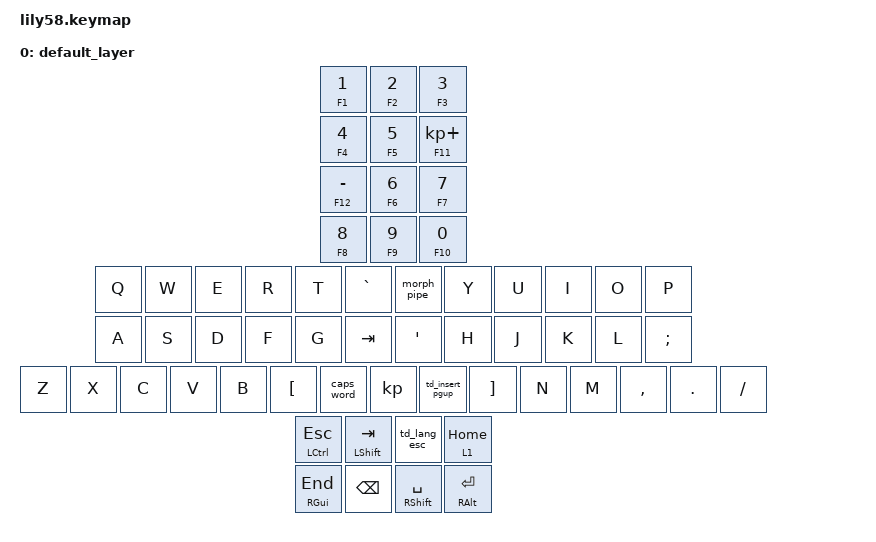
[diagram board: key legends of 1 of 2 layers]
/*
 * Copyright (c) 2020 The ZMK Contributors
 *
 * SPDX-License-Identifier: MIT
 */

#include <behaviors.dtsi>
#include <dt-bindings/zmk/bt.h>
#include <dt-bindings/zmk/keys.h>

/ {
  macros {
    lang: lang {
      compatible = "zmk,behavior-macro";
      #binding-cells = <0>;
      bindings =
        <&macro_press &kp LCTRL>,
        <&macro_tap &kp LSHFT>,
        <&macro_release &kp LCTRL>;
    };
    expipe: expipe {
      compatible = "zmk,behavior-macro";
      #binding-cells = <0>;
      bindings =
        <&macro_tap &kp PIPE>,
        <&macro_tap &kp GT>;
    };
  };
};

/ {
    behaviors {
      ht_tp: ht_tp {
        compatible = "zmk,behavior-hold-tap";
        #binding-cells = <2>;
        flavor = "tap-preferred";
        tapping-term-ms = <500>;
        quick-tap-ms = <500>;
        bindings = <&kp>, <&kp>;
      };
      td_lang_esc: td_lang_esc {
        compatible = "zmk,behavior-tap-dance";
        #binding-cells = <0>;
        tapping-term-ms = <500>;
        bindings =
          <&lang>,
          <&kp ESC>;
      };
      td_prnt_cw: td_prnt_cw {
        compatible = "zmk,behavior-tap-dance";
        #binding-cells = <0>;
        tapping-term-ms = <500>;
        bindings =
          <&kp PSCRN>,
          <&caps_word>;
      };
      td_bspc_ret: td_bspc_ret {
        compatible = "zmk,behavior-tap-dance";
        #binding-cells = <0>;
        tapping-term-ms = <500>;
        bindings =
          <&kp BSPC>,
          <&kp RET>;
      };
      td_insert_pgup: td_insert_pgup {
        compatible = "zmk,behavior-tap-dance";
        #binding-cells = <0>;
        tapping-term-ms = <500>;
        bindings =
          <&kp INSERT>,
          <&kp PG_UP>;
      };
      td_end_win_pgdn: td_end_win_pgdn {
        compatible = "zmk,behavior-tap-dance";
        #binding-cells = <0>;
        tapping-term-ms = <500>;
        bindings =
          <&mt RGUI END>,
          <&kp PG_DN>;
      };
      morph_pipe: morph_pipe {
        compatible = "zmk,behavior-mod-morph";
        #binding-cells = <0>;
        bindings = <&expipe>, <&kp PIPE>;
        mods = <(MOD_LSFT)>;
      };
    };

    keymap {
        compatible = "zmk,keymap";

        default_layer {
            bindings = <
&ht_tp F1 N1    &ht_tp F2 N2    &ht_tp F3 N3
&ht_tp F4 N4    &ht_tp F5 N5    &ht_tp F11 KP_PLUS
                                                                          &ht_tp F12 MINUS     &ht_tp F6 N6      &ht_tp F7 N7
                                                                          &ht_tp F8 N8         &ht_tp F9 N9      &ht_tp F10 N0
&kp Q   &kp W   &kp E   &kp R   &kp T     &kp GRAVE                       &morph_pipe   &kp Y     &kp U  &kp I      &kp O      &kp P
&kp A   &kp S   &kp D   &kp F   &kp G     &kp TAB                         &kp SQT    &kp H     &kp J  &kp K      &kp L      &kp SEMI
&kp Z   &kp X   &kp C   &kp V   &kp B     &kp LBKT &caps_word &kp &td_insert_pgup  &kp RBKT   &kp N     &kp M  &kp COMMA  &kp DOT    &kp FSLH
                  &mt LCTRL ESC   &mt LSHIFT TAB  &td_lang_esc  &lt 1 HOME
                                                  &mt RGUI END    &kp BSPC           &mt RSHIFT SPACE   &mt RALT RET
            >;
        };

        lower_layer {

            bindings = <
&kp F1     &kp F2        &kp F3        &kp F4      &kp F5        &kp F11                         &kp F12     &kp F6        &kp F7        &kp F8       &kp F9       &kp F10
&trans     &trans        &trans        &trans      &trans        &trans                          &kp BSLH     &trans        &trans        &trans        &trans        &trans
&trans     &trans        &trans        &trans      &trans        &trans                          &kp HOME     &kp LEFT      &kp DOWN      &kp UP        &kp RIGHT     &kp END
&trans     &trans        &trans        &trans      &trans        &trans        &trans    &trans  &trans     &trans        &trans        &trans        &trans        &trans
                                       &trans      &trans        &trans        &trans    &trans  &kp DELETE     &trans        &trans
            >;
        };
    };
};

// &bt BT_CLR &bt BT_SEL 0  &bt BT_SEL 1  &bt BT_SEL 2  &bt BT_SEL 3  &bt BT_SEL 4
